# CY8C5888LTI_LP097 register map
File version: 0.1
CY8C58LP
Registers are 8-bit, read-write, no defined reset value unless marked. A register's access mark holds for its fields unless they carry their own. Offsets are from the block's base; lines under a group give offsets from that group; [hi:lo] are bit positions; {n}, {i} and the like mark numbered series; 'fields as' and 'values as' point back to an identical list; <NAME> marks a mode.

## Memory map
0x00000000 UART_1 — UART
0x00000000 PWM_4
0x00000000 PWM_3
0x00000000 PWM_1
0x00000000 PWM_2
0x00000000 SPI

## UART_1 — UART
Base 0x00000000
0x40006448 TX_UART_1_TX_DATA — TX Data Register
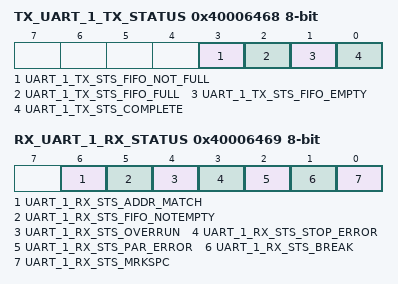
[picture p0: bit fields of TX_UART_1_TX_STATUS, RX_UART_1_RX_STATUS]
0x40006468 TX_UART_1_TX_STATUS — TX status register
  [3] UART_1_TX_STS_FIFO_NOT_FULL ro, [2] UART_1_TX_STS_FIFO_FULL ro, [1] UART_1_TX_STS_FIFO_EMPTY ro, [0] UART_1_TX_STS_COMPLETE ro
0x40006469 RX_UART_1_RX_STATUS — RX status register
  [6] UART_1_RX_STS_ADDR_MATCH ro, [5] UART_1_RX_STS_FIFO_NOTEMPTY ro, [4] UART_1_RX_STS_OVERRUN ro, [3] UART_1_RX_STS_STOP_ERROR ro, [2] UART_1_RX_STS_PAR_ERROR ro, [1] UART_1_RX_STS_BREAK ro, [0] UART_1_RX_STS_MRKSPC ro
0x40006529 RX_UART_1_RX_ADDRESS1 — RX Address1 Register
0x40006539 RX_UART_1_RX_ADDRESS2 — RX Address2 Register
0x40006549 RX_UART_1_RX_DATA — RX Data Register

## PWM_4
Base 0x00000000
0x40006422 PWM_4_COMPARE_Reg 16-bit — UDB.D0 - Assigned Compare Value
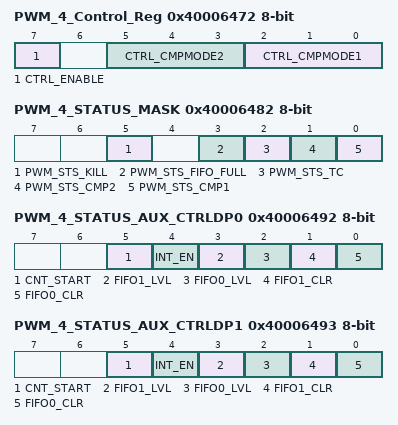
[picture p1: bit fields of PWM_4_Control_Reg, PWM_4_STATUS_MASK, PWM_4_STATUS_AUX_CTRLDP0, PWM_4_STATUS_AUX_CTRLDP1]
0x40006472 PWM_4_Control_Reg — UDB Control Register - Assigned Control Register Value
  [7] CTRL_ENABLE — Enable the PWM
  [5:3] CTRL_CMPMODE2 — Compare mode 2
  [2:0] CTRL_CMPMODE1 — Compare mode 1
0x40006482 PWM_4_STATUS_MASK — UDB Status bits Interrupt Mask Enable Register
  [5] PWM_STS_KILL ro — Enables the Interrupt on Kill
  [3] PWM_STS_FIFO_FULL ro — FIFO Full Status Mask
  [2] PWM_STS_TC ro — Enables the Interrupt on Terminal Count
  [1] PWM_STS_CMP2 ro — Enables the Interrupt on Compare 2
  [0] PWM_STS_CMP1 ro — Enables the Interrupt on Compare 1
0x40006492 PWM_4_STATUS_AUX_CTRLDP0 — UDB Auxilliary Control Register
  [5] CNT_START — FIFO0 clear
    0=E_CNT_START0 (Disable counter); 1=E_CNT_START1 (Enable counter)
  [4] INT_EN
    0=E_INT_EN0 (Interrupt disabled); 1=E_INT_EN1 (Interrupt enabled)
  [3] FIFO1_LVL — FIFO level
    0=E_FIFO_LVL_0 (FIFO LVL: input mode: FIFO not full; output mode: FIFO not empty); 1=E_FIFO_LVL_1 (FIFO LVL: input mode: FIFO at least 1/2 empty; output mode: FIFO at least 1/2 full)
  [2] FIFO0_LVL — FIFO level
    values as FIFO1_LVL
  [1] FIFO1_CLR — FIFO1 clear
    0=E_FIFO_CLR_0 (Normal FIFO operation); 1=E_FIFO_CLR_1 (Clear FIFO state)
  [0] FIFO0_CLR — FIFO0 clear
    values as FIFO1_CLR
0x40006493 PWM_4_STATUS_AUX_CTRLDP1 — UDB Auxilliary Control Register
  fields as PWM_4_STATUS_AUX_CTRLDP0

## PWM_3
Base 0x00000000
0x40006424 PWM_3_COMPARE_Reg 16-bit — UDB.D0 - Assigned Compare Value
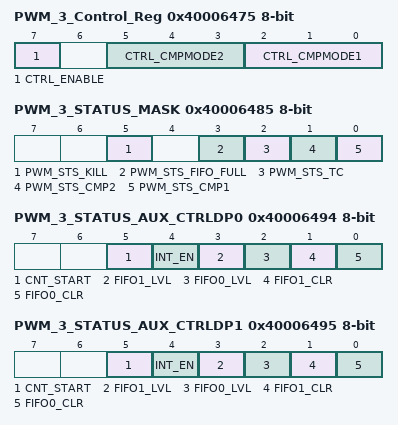
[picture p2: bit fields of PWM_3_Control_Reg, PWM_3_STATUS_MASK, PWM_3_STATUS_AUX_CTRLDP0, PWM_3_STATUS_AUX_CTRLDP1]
0x40006475 PWM_3_Control_Reg — UDB Control Register - Assigned Control Register Value
  [7] CTRL_ENABLE — Enable the PWM
  [5:3] CTRL_CMPMODE2 — Compare mode 2
  [2:0] CTRL_CMPMODE1 — Compare mode 1
0x40006485 PWM_3_STATUS_MASK — UDB Status bits Interrupt Mask Enable Register
  [5] PWM_STS_KILL ro — Enables the Interrupt on Kill
  [3] PWM_STS_FIFO_FULL ro — FIFO Full Status Mask
  [2] PWM_STS_TC ro — Enables the Interrupt on Terminal Count
  [1] PWM_STS_CMP2 ro — Enables the Interrupt on Compare 2
  [0] PWM_STS_CMP1 ro — Enables the Interrupt on Compare 1
0x40006494 PWM_3_STATUS_AUX_CTRLDP0 — UDB Auxilliary Control Register
  [5] CNT_START — FIFO0 clear
    0=E_CNT_START0 (Disable counter); 1=E_CNT_START1 (Enable counter)
  [4] INT_EN
    0=E_INT_EN0 (Interrupt disabled); 1=E_INT_EN1 (Interrupt enabled)
  [3] FIFO1_LVL — FIFO level
    0=E_FIFO_LVL_0 (FIFO LVL: input mode: FIFO not full; output mode: FIFO not empty); 1=E_FIFO_LVL_1 (FIFO LVL: input mode: FIFO at least 1/2 empty; output mode: FIFO at least 1/2 full)
  [2] FIFO0_LVL — FIFO level
    values as FIFO1_LVL
  [1] FIFO1_CLR — FIFO1 clear
    0=E_FIFO_CLR_0 (Normal FIFO operation); 1=E_FIFO_CLR_1 (Clear FIFO state)
  [0] FIFO0_CLR — FIFO0 clear
    values as FIFO1_CLR
0x40006495 PWM_3_STATUS_AUX_CTRLDP1 — UDB Auxilliary Control Register
  fields as PWM_3_STATUS_AUX_CTRLDP0
